VERSION ""

NS_ :

BS_:

BU_: LV_Box

BO_ 1696 LV_Box_Analog: 3 LV_Box
 SG_ LVBOX_PWR : 0|12@1+ (0.0029304029304029304,0) [0|12] "V" Vector__XXX
 SG_ TSAL_PWR : 12|12@1+ (0.0029304029304029304,0) [0|12] "V" Vector__XXX

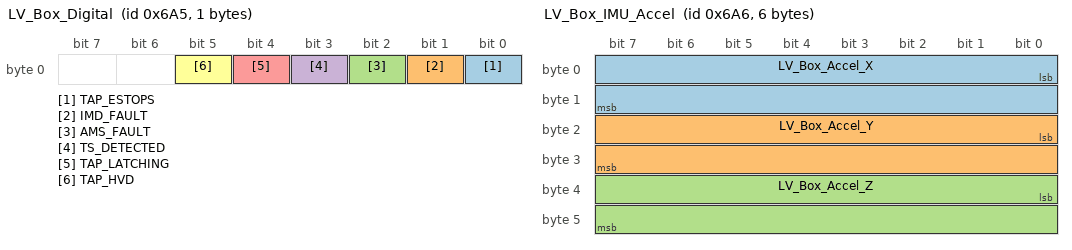
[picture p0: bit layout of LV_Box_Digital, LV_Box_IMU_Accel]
BO_ 1701 LV_Box_Digital: 1 LV_Box
 SG_ TAP_ESTOPS : 0|1@1+ (1,0) [0|1] "bool" Vector__XXX
 SG_ IMD_FAULT : 1|1@1+ (1,0) [0|1] "bool" Vector__XXX
 SG_ AMS_FAULT : 2|1@1+ (1,0) [0|1] "bool" Vector__XXX
 SG_ TS_DETECTED : 3|1@1+ (1,0) [0|1] "bool" Vector__XXX
 SG_ TAP_LATCHING : 4|1@1+ (1,0) [0|1] "bool" Vector__XXX
 SG_ TAP_HVD : 5|1@1+ (1,0) [0|1] "bool" Vector__XXX

BO_ 1702 LV_Box_IMU_Accel: 6 LV_Box
 SG_ LV_Box_Accel_X : 0|16@1- (0.000122,0) [-4|4] "g" Vector__XXX
 SG_ LV_Box_Accel_Y : 16|16@1- (0.000122,0) [-4|4] "g" Vector__XXX
 SG_ LV_Box_Accel_Z : 32|16@1- (0.000122,0) [-4|4] "g" Vector__XXX

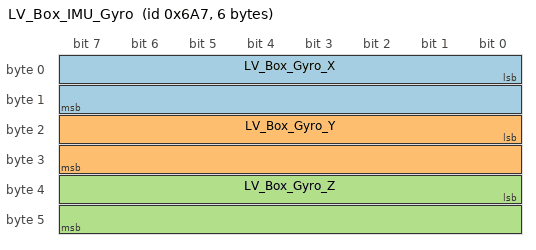
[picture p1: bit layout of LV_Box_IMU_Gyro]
BO_ 1703 LV_Box_IMU_Gyro: 6 LV_Box
 SG_ LV_Box_Gyro_X : 0|16@1- (0.0175,0) [-500|500] "dps" Vector__XXX
 SG_ LV_Box_Gyro_Y : 16|16@1- (0.0175,0) [-500|500] "dps" Vector__XXX
 SG_ LV_Box_Gyro_Z : 32|16@1- (0.0175,0) [-500|500] "dps" Vector__XXX

BO_ 1704 LV_Box_Temp: 4 LV_Box
 SG_ LV_Box_IMU_Temp : 0|16@1- (0.00390625,25) [-40|85] "degC" Vector__XXX
 SG_ LV_Box_Ambient_Temp : 16|16@1- (0.0625,0) [-55|125] "degC" Vector__XXX

BO_ 1705 LV_Box_Status: 1 LV_Box
 SG_ LV_Box_ISM330_OK : 0|1@1+ (1,0) [0|1] "" Vector__XXX
 SG_ LV_Box_MCP9800_OK : 1|1@1+ (1,0) [0|1] "" Vector__XXX
